# haltium_flpr register map
Vendor: Nordic Semiconductor; Series: nRFHaltium; File version: 1
Registers are 32-bit, read-write, reset 0x0 unless marked. A register's access mark holds for its fields unless they carry their own. Offsets are from the block's base; [hi:lo] are bit positions; {n}, {i} and the like mark numbered series; 'fields as' and 'values as' point back to an identical list.

## GLOBAL_USBHSCORE0_NS (part 1 of 2) — USBHSCORE
Base 0x2F700000
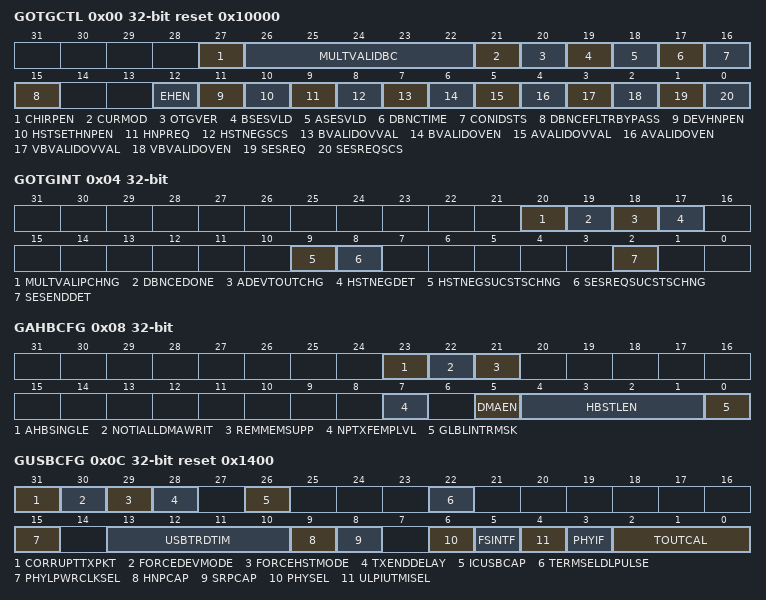
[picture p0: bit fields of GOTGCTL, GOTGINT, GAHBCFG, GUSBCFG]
0x00 GOTGCTL reset 0x10000 — OTG Control and Status Register
  [27] CHIRPEN — Mode: Device Only
    0=CHIRP_DISABLE (Unspecified); 1=CHIRP_ENABLE (Unspecified)
  [26:22] MULTVALIDBC ro — Mode: Host and Device. Multi Valued ID pin (MultValIdBC)
    1=RID_C (Unspecified); 2=RID_B (Unspecified); 4=RID_A (Unspecified); 8=RID_GND (Unspecified); 16=RID_FLOAT (Unspecified)
  [21] CURMOD ro — Current Mode of Operation (CurMod)
    0=DEVICEMODE (Unspecified); 1=HOSTMODE (Unspecified)
  [20] OTGVER — OTG Version (OTGVer)
    0=VER13 (Unspecified); 1=VER20 (Unspecified)
  [19] BSESVLD ro — Mode: Device only. B-Session Valid (BSesVld)
    0=NOTVALID (Unspecified); 1=VALID (Unspecified)
  [18] ASESVLD ro — Mode: Host only. A-Session Valid (ASesVld)
    0=NOTVALID (Unspecified); 1=VALID (Unspecified)
  [17] DBNCTIME ro — Mode: Host only. Long/Short Debounce Time (DbncTime)
    0=LONG (Unspecified); 1=SHORT (Unspecified)
  [16] CONIDSTS ro — Mode: Host and Device. Connector ID Status (ConIDSts)
    0=MODEA (Unspecified); 1=MODEB (Unspecified)
  [15] DBNCEFLTRBYPASS — Mode: Host and Device
    0=DISABLED (Unspecified); 1=ENABLED (Unspecified)
  [12] EHEN — Mode: SRP Capable Host. Embedded Host Enable (EHEn)
    0=EHDISABLE (Unspecified); 1=EHENABLE (Unspecified)
  [11] DEVHNPEN — Mode: HNP Capable OTG DeviceDevice HNP Enabled (DevHNPEn)
    0=DISABLED (Unspecified); 1=ENABLED (Unspecified)
  [10] HSTSETHNPEN — Mode: HNP Capable OTG Host. Host Set HNP Enable (HstSetHNPEn)
    0=DISABLED (Unspecified); 1=ENABLED (Unspecified)
  [9] HNPREQ — Mode: HNP Capable OTG DeviceHNP Request (HNPReq)
    0=DISABLED (Unspecified); 1=ENABLED (Unspecified)
  [8] HSTNEGSCS ro — Mode: HNP-capable DeviceHost Negotiation Success (HstNegScs)
    0=FAIL (Unspecified); 1=SUCCESS (Unspecified)
  [7] BVALIDOVVAL — Mode: Device only. B-Peripheral Session Valid OverrideValue (BvalidOvVal)
    0=Unspecified; 1=Unspecified
  [6] BVALIDOVEN — Mode: Device only. B-Peripheral Session Valid Override Value (BvalidOvEn)
    0=DISABLED (Unspecified); 1=ENABLED (Unspecified)
  [5] AVALIDOVVAL — Mode: Host only A-Peripheral Session Valid OverrideValue (AvalidOvVal)
    0=Unspecified; 1=Unspecified
  [4] AVALIDOVEN — Mode: Host only. A-Peripheral Session Valid Override Enable (AvalidOvEn)
    0=DISABLED (Unspecified); 1=ENABLED (Unspecified)
  [3] VBVALIDOVVAL — Mode: Host only. VBUS Valid OverrideValue (VbvalidOvVal)
    0=SET0 (Unspecified); 1=SET1 (Unspecified)
  [2] VBVALIDOVEN — Mode: Host only. VBUS Valid Override Enable (VbvalidOvEn)
    0=DISABLED (Unspecified); 1=ENABLED (Unspecified)
  [1] SESREQ — Mode: Device only. Session Request (SesReq)
    0=NOREQUEST (Unspecified); 1=REQUEST (Unspecified)
  [0] SESREQSCS ro — Mode: Device only. Session Request Success (SesReqScs)
    0=FAIL (Unspecified); 1=SUCCESS (Unspecified)
0x04 GOTGINT — OTG Interrupt Register
  [20] MULTVALIPCHNG — This bit when set indicates that there is a change in the value of at least one ACA pin value.
    0=NO_ACA_PIN_CHANGE (Unspecified); 1=ACA_PIN_CHANGE (Unspecified)
  [19] DBNCEDONE — Mode: Host only. Debounce Done (DbnceDone)
    0=INACTIVE (Unspecified); 1=ACTIVE (Unspecified)
  [18] ADEVTOUTCHG — Mode: Host and Device. A-Device Timeout Change (ADevTOUTChg)
    0=INACTIVE (Unspecified); 1=ACTIVE (Unspecified)
  [17] HSTNEGDET — Mode:Host and Device. Host Negotiation Detected (HstNegDet)
    0=INACTIVE (Unspecified); 1=ACTIVE (Unspecified)
  [9] HSTNEGSUCSTSCHNG — Mode: Host and Device. Host Negotiation Success Status Change (HstNegSucStsChng)
    0=INACTIVE (Unspecified); 1=ACTIVE (Unspecified)
  [8] SESREQSUCSTSCHNG — Mode: Host and Device. Session Request Success Status Change (SesReqSucStsChng)
    0=INACTIVE (Unspecified); 1=ACTIVE (Unspecified)
  [2] SESENDDET — Mode: Host and Device. Session End Detected (SesEndDet)
    0=INACTIVE (Unspecified); 1=ACTIVE (Unspecified)
0x08 GAHBCFG — AHB Configuration Register
  [23] AHBSINGLE — Mode: Host and Device. AHB Single Support (AHBSingle)
    0=INCRBURST (Unspecified); 1=SINGLEBURST (Unspecified)
  [22] NOTIALLDMAWRIT — Mode: Host and Device. Notify All DMA Write Transactions (NotiAllDmaWrit)
    0=LASTTRANS (Unspecified); 1=ALLTRANS (Unspecified)
  [21] REMMEMSUPP — Mode: Host and Device. Remote Memory Support (RemMemSupp)
    0=DISABLED (Unspecified); 1=ENABLED (Unspecified)
  [7] NPTXFEMPLVL — Mode: Host and device. Non-Periodic TxFIFO Empty Level (NPTxFEmpLvl)
    0=HALFEMPTY (Unspecified); 1=EMPTY (Unspecified)
  [5] DMAEN — Mode: Host and device. DMA Enable (DMAEn)
    0=SLAVEMODE (Unspecified); 1=DMAMODE (Unspecified)
  [4:1] HBSTLEN — Mode: Host and device. Burst Length/Type (HBstLen)
    0=WORD1ORSINGLE (Unspecified); 1=WORD4ORINCR (Unspecified); 2=WORD8 (Unspecified); 3=WORD16ORINCR4 (Unspecified); 4=WORD32 (Unspecified); 5=WORD64ORINCR8 (Unspecified); 6=WORD128 (Unspecified); 7=WORD256ORINCR16 (Unspecified); 8=WORDX (Unspecified)
  [0] GLBLINTRMSK — Mode: Host and device. Global Interrupt Mask (GlblIntrMsk)
    0=MASK (Unspecified); 1=NOMASK (Unspecified)
0x0C GUSBCFG reset 0x1400 — USB Configuration Register
  [31] CORRUPTTXPKT wo — Mode: Host and device. Corrupt Tx packet (CorruptTxPkt)
    0=Disabled (Unspecified); 1=Enabled (Unspecified)
  [30] FORCEDEVMODE — Mode:Host and device. Force Device Mode (ForceDevMode)
    0=DISABLED (Unspecified); 1=ENABLED (Unspecified)
  [29] FORCEHSTMODE — Mode: Host and device. Force Host Mode (ForceHstMode)
    0=DISABLED (Unspecified); 1=ENABLED (Unspecified)
  [28] TXENDDELAY — Mode: Device only. Tx End Delay (TxEndDelay)
    0=DISABLED (Unspecified); 1=ENABLED (Unspecified)
  [26] ICUSBCAP ro — Mode: Host and Device. IC_USB-Capable (IC_USBCap)
    0=NOTSELECTED (Unspecified); 1=SELECTED (Unspecified)
  [22] TERMSELDLPULSE — Mode: Device only. TermSel DLine Pulsing Selection (TermSelDLPulse)
    0=TXVALID (Unspecified); 1=TERMSEL (Unspecified)
  [15] PHYLPWRCLKSEL — PHY Low-Power Clock Select (PhyLPwrClkSel)
    0=INTPLLCLK (Unspecified); 1=EXTCLK (Unspecified)
  [13:10] USBTRDTIM — Mode: Device only. USB Turnaround Time (USBTrdTim)
    5=TURNTIME16BIT (Unspecified); 9=TURNTIME8BIT (Unspecified)
  [9] HNPCAP — Mode: Host and Device. HNP-Capable (HNPCap)
    0=DISABLED (Unspecified); 1=ENABLED (Unspecified)
  [8] SRPCAP — Mode: Host and Device. SRP-Capable (SRPCap)
    0=DISABLED (Unspecified); 1=ENABLED (Unspecified)
  [6] PHYSEL ro
    0=USB20 (Unspecified); 1=USB11 (Unspecified)
  [5] FSINTF ro — Mode: Host and Device. Full-Speed Serial Interface Select (FSIntf)
    0=FS6PIN (Unspecified); 1=FS3PIN (Unspecified)
  [4] ULPIUTMISEL ro — Mode: Host and Device. ULPI or UTMI+ Select (ULPI_UTMI_Sel)
    0=UTMI (Unspecified); 1=ULPI (Unspecified)
  [3] PHYIF — Mode: Host and Device. PHY Interface (PHYIf)
    0=BITS8 (Unspecified); 1=BITS16 (Unspecified)
  [2:0] TOUTCAL — Mode: Host and Device. HS/FS Timeout Calibration (TOutCal)
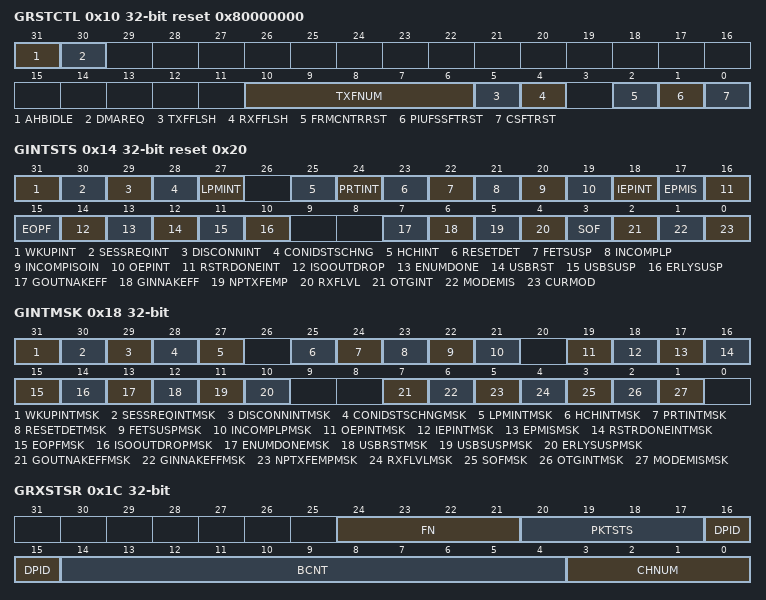
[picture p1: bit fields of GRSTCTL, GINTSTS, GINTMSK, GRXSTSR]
0x10 GRSTCTL reset 0x80000000 — Reset Register
  [31] AHBIDLE ro — Mode: Host and Device. AHB Master Idle (AHBIdle)
    0=INACTIVE (Unspecified); 1=ACTIVE (Unspecified)
  [30] DMAREQ ro — Mode: Host and Device. DMA Request Signal (DMAReq)
    0=INACTIVE (Unspecified); 1=ACTIVE (Unspecified)
  [10:6] TXFNUM — Mode: Host and Device. TxFIFO Number (TxFNum)
    {v}=TXF{v} (Unspecified) (v=0..16)
  [5] TXFFLSH — Mode: Host and Device. TxFIFO Flush (TxFFlsh)
    0=INACTIVE (Unspecified); 1=ACTIVE (Unspecified)
  [4] RXFFLSH — Mode: Host and Device. RxFIFO Flush (RxFFlsh)
    0=INACTIVE (Unspecified); 1=ACTIVE (Unspecified)
  [2] FRMCNTRRST — Mode: Host only. Host Frame Counter Reset (FrmCntrRst)
    0=NOTACTIVE (Unspecified); 1=ACTIVE (Unspecified)
  [1] PIUFSSFTRST — Mode: Host and Device. PIU FS Dedicated Controller Soft Reset (PIUFSSftRst)
    0=RESET_INACTIVE (Unspecified); 1=RESET_ACTIVE (Unspecified)
  [0] CSFTRST — Mode: Host and Device. Core Soft Reset (CSftRst)
    0=NOTACTIVE (Unspecified); 1=ACTIVE (Unspecified)
0x14 GINTSTS reset 0x20 — Interrupt Register
  [31] WKUPINT — Mode: Host and Device. Resume/Remote Wakeup Detected Interrupt (WkUpInt)
    0=INACTIVE (Unspecified); 1=ACTIVE (Unspecified)
  [30] SESSREQINT — Mode: Host and Device. Session Request/New Session Detected Interrupt (SessReqInt)
    0=INACTIVE (Unspecified); 1=ACTIVE (Unspecified)
  [29] DISCONNINT — Mode: Host only. Disconnect Detected Interrupt (DisconnInt)
    0=INACTIVE (Unspecified); 1=ACTIVE (Unspecified)
  [28] CONIDSTSCHNG — Mode: Host and Device. Connector ID Status Change (ConIDStsChng)
    0=INACTIVE (Unspecified); 1=ACTIVE (Unspecified)
  [27] LPMINT — Mode: Host and Device
    0=INACTIVE (Unspecified); 1=ACTIVE (Unspecified)
  [25] HCHINT ro — Mode: Host only. Host Channels Interrupt (HChInt)
    0=INACTIVE (Unspecified); 1=ACTIVE (Unspecified)
  [24] PRTINT ro — Mode: Host only. Host Port Interrupt (PrtInt)
    0=INACTIVE (Unspecified); 1=ACTIVE (Unspecified)
  [23] RESETDET — Mode: Device only. Reset detected Interrupt (ResetDet)
    0=INACTIVE (Unspecified); 1=ACTIVE (Unspecified)
  [22] FETSUSP — Mode: Device only. Data Fetch Suspended (FetSusp)
    0=INACTIVE (Unspecified); 1=ACTIVE (Unspecified)
  [21] INCOMPLP — Incomplete Periodic Transfer (incomplP)
    0=INACTIVE (Unspecified); 1=ACTIVE (Unspecified)
  [20] INCOMPISOIN — Mode: Device only. Incomplete Isochronous IN Transfer (incompISOIN)
    0=INACTIVE (Unspecified); 1=ACTIVE (Unspecified)
  [19] OEPINT ro — Mode: Device only. OUT Endpoints Interrupt (OEPInt)
    0=INACTIVE (Unspecified); 1=ACTIVE (Unspecified)
  [18] IEPINT ro — Mode: Device only. IN Endpoints Interrupt (IEPInt)
    0=INACTIVE (Unspecified); 1=ACTIVE (Unspecified)
  [17] EPMIS — Mode: Device only. Endpoint Mismatch Interrupt (EPMis)
    0=INACTIVE (Unspecified); 1=ACTIVE (Unspecified)
  [16] RSTRDONEINT — Mode: Device only. Restore Done Interrupt (RstrDoneInt)
    0=INACTIVE (Unspecified); 1=ACTIVE (Unspecified)
  [15] EOPF — Mode: Device only. End of Periodic Frame Interrupt (EOPF)
    0=INACTIVE (Unspecified); 1=ACTIVE (Unspecified)
  [14] ISOOUTDROP — Mode: Device only. Isochronous OUT Packet Dropped Interrupt (ISOOutDrop)
    0=INACTIVE (Unspecified); 1=ACTIVE (Unspecified)
  [13] ENUMDONE — Mode: Device only. Enumeration Done (EnumDone)
    0=INACTIVE (Unspecified); 1=ACTIVE (Unspecified)
  [12] USBRST — Mode: Device only. USB Reset (USBRst)
    0=INACTIVE (Unspecified); 1=ACTIVE (Unspecified)
  [11] USBSUSP — Mode: Device only. USB Suspend (USBSusp)
    0=INACTIVE (Unspecified); 1=ACTIVE (Unspecified)
  [10] ERLYSUSP — Mode: Device only. Early Suspend (ErlySusp)
    0=INACTIVE (Unspecified); 1=ACTIVE (Unspecified)
  [7] GOUTNAKEFF ro — Mode: Device only. Global OUT NAK Effective (GOUTNakEff)
    0=INACTIVE (Unspecified); 1=ACTIVE (Unspecified)
  [6] GINNAKEFF ro — Mode: Device only. Global IN Non-periodic NAK Effective (GINNakEff)
    0=INACTIVE (Unspecified); 1=ACTIVE (Unspecified)
  [5] NPTXFEMP ro — Mode: Host and Device. Non-periodic TxFIFO Empty (NPTxFEmp)
    0=INACTIVE (Unspecified); 1=ACTIVE (Unspecified)
  [4] RXFLVL ro — Mode: Host and Device. RxFIFO Non-Empty (RxFLvl)
    0=INACTIVE (Unspecified); 1=ACTIVE (Unspecified)
  [3] SOF — Mode: Host and Device. Start of (micro)Frame (Sof)
    0=INTACTIVE (Unspecified); 1=ACTIVE (Unspecified)
  [2] OTGINT ro — Mode: Host and Device. OTG Interrupt (OTGInt)
    0=INACTIVE (Unspecified); 1=ACTIVE (Unspecified)
  [1] MODEMIS — Mode: Host and Device. Mode Mismatch Interrupt (ModeMis)
    0=INACTIVE (Unspecified); 1=ACTIVE (Unspecified)
  [0] CURMOD ro — Mode: Host and Device. Current Mode of Operation (CurMod)
    0=DEVICE (Unspecified); 1=HOST (Unspecified)
0x18 GINTMSK — Interrupt Mask Register
  [all] fields
    0=MASK (Unspecified); 1=NOMASK (Unspecified)
  [31] WKUPINTMSK — Mode: Host and Device. Resume/Remote Wakeup Detected Interrupt Mask (WkUpIntMsk)
  [30] SESSREQINTMSK — Mode: Host and Device
  [29] DISCONNINTMSK — Mode: Host and Device
  [28] CONIDSTSCHNGMSK — Mode: Host and Device
  [27] LPMINTMSK — Mode: Host and Device. LPM Transaction Received Interrupt (LPM_Int)
  [25] HCHINTMSK — Mode: Host only. Host Channels Interrupt Mask (HChIntMsk)
  [24] PRTINTMSK — Mode: Host only. Host Port Interrupt Mask (PrtIntMsk)
  [23] RESETDETMSK — Mode: Device only. Reset detected Interrupt Mask (ResetDetMsk)
  [22] FETSUSPMSK — Mode: Device only. Data Fetch Suspended Mask (FetSuspMsk)
  [21] INCOMPLPMSK — Incomplete Periodic Transfer Mask (incomplPMsk)
  [19] OEPINTMSK — Mode: Device only. OUT Endpoints Interrupt Mask (OEPIntMsk)
  [18] IEPINTMSK — Mode: Device only. IN Endpoints Interrupt Mask (IEPIntMsk)
  [17] EPMISMSK — Mode: Device only. Endpoint Mismatch Interrupt Mask (EPMisMsk)
  [16] RSTRDONEINTMSK — Mode: Host and Device
  [15] EOPFMSK — Mode: Device only. End of Periodic Frame Interrupt Mask (EOPFMsk)
  [14] ISOOUTDROPMSK — Mode: Device only. Isochronous OUT Packet Dropped Interrupt Mask (ISOOutDropMsk)
  [13] ENUMDONEMSK — Mode: Device only. Enumeration Done Mask (EnumDoneMsk)
  [12] USBRSTMSK — Mode: Device only. USB Reset Mask (USBRstMsk)
  [11] USBSUSPMSK — Mode: Device only. USB Suspend Mask (USBSuspMsk)
  [10] ERLYSUSPMSK — Mode: Device only. Early Suspend Mask (ErlySuspMsk)
  [7] GOUTNAKEFFMSK — Mode: Device only. Global OUT NAK Effective Mask (GOUTNakEffMsk)
  [6] GINNAKEFFMSK — Mode: Device only,
  [5] NPTXFEMPMSK — Mode: Host and Device
  [4] RXFLVLMSK — Mode: Host and Device
  [3] SOFMSK — Mode: Host and Device
  [2] OTGINTMSK — Mode: Host and Device
  [1] MODEMISMSK — Mode: Host and Device
0x1C GRXSTSR — Receive Status Debug Read Register
  [24:21] FN ro — Mode: Device only. Frame Number (FN)
  [20:17] PKTSTS ro — Packet Status (PktSts) indicates the status of the received packet.
    1=OUTNAK (Unspecified); 2=INOUTDPRX (Unspecified); 3=INOUTTRCOM (Unspecified); 4=DSETUPCOM (Unspecified); 5=DTTOG (Unspecified); 6=DSETUPRX (Unspecified); 7=CHHALT (Unspecified)
  [16:15] DPID ro — Data PID (DPID)
    0=DATA0 (Unspecified); 1=DATA2 (Unspecified); 2=DATA1 (Unspecified); 3=MDATA (Unspecified)
  [14:4] BCNT ro — Byte Count (BCnt)
  [3:0] CHNUM ro — Channel Number (ChNum)
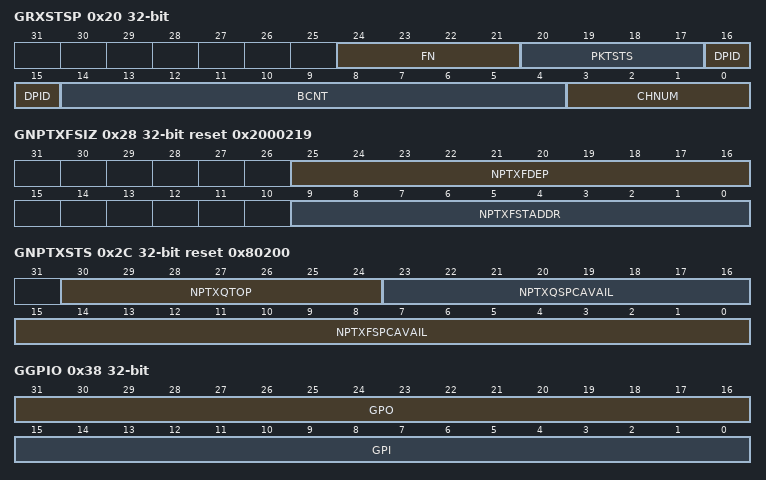
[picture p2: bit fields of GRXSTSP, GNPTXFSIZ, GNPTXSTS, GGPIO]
0x20 GRXSTSP — Receive Status Read/Pop Register
  [24:21] FN ro — Mode: Device only. Frame Number (FN)
  [20:17] PKTSTS ro — Packet Status (PktSts) indicates the status of the received packet.
    1=OUTNAK (Unspecified); 2=INOUTDPRX (Unspecified); 3=INOUTTRCOM (Unspecified); 4=DSETUPCOM (Unspecified); 5=DTTOG (Unspecified)
  [16:15] DPID ro — Data PID (DPID)
    values as GRXSTSR.DPID
  [14:4] BCNT ro — Byte Count (BCnt)
  [3:0] CHNUM ro — Channel Number (ChNum)
    {v}=CHEP{v} (Unspecified) (v=0..15)
0x24 GRXFSIZ reset 0x219 — Receive FIFO Size Register
  [9:0] RXFDEP — Mode: Host and Device. RxFIFO Depth (RxFDep)
0x28 GNPTXFSIZ reset 0x2000219 — Non-periodic Transmit FIFO Size Register
  [25:16] NPTXFDEP — Mode: Host only. Non-periodic TxFIFO Depth (NPTxFDep)
  [9:0] NPTXFSTADDR — Non-periodic Transmit RAM Start Address (NPTxFStAddr)
0x2C GNPTXSTS reset 0x80200 — Non-periodic Transmit FIFO/Queue Status Register
  [30:24] NPTXQTOP ro — Top of the Non-periodic Transmit Request Queue (NPTxQTop)
    0=INOUTTK (Unspecified); 1=ZEROTX (Unspecified); 2=PINGCSPLIT (Unspecified); 3=CHNHALT (Unspecified)
  [23:16] NPTXQSPCAVAIL ro — Non-periodic Transmit Request Queue Space Available (NPTxQSpcAvail)
    0=FULL (Unspecified); {v}=QUE{v} (Unspecified) (v=1..8)
  [15:0] NPTXFSPCAVAIL ro — Non-periodic TxFIFO Space Avail (NPTxFSpcAvail)
0x38 GGPIO — General Purpose Input/Output Register
  [31:16] GPO — General Purpose Output (GPO)
  [15:0] GPI ro — General Purpose Input (GPI)
0x3C GUID reset 0x12345678 — User ID Register
  [31:0] GUID — User ID (UserID)
0x40 GSNPSID reset 0x4F54400A — Synopsys ID Register
  [31:0] SYNOPSYSID ro — Release number of the controller being used currently.
0x44 GHWCFG1 reset 0xAA555000 — User Hardware Configuration 1 Register
  [31:0] EPDIR ro — This 32-bit field uses two bits per
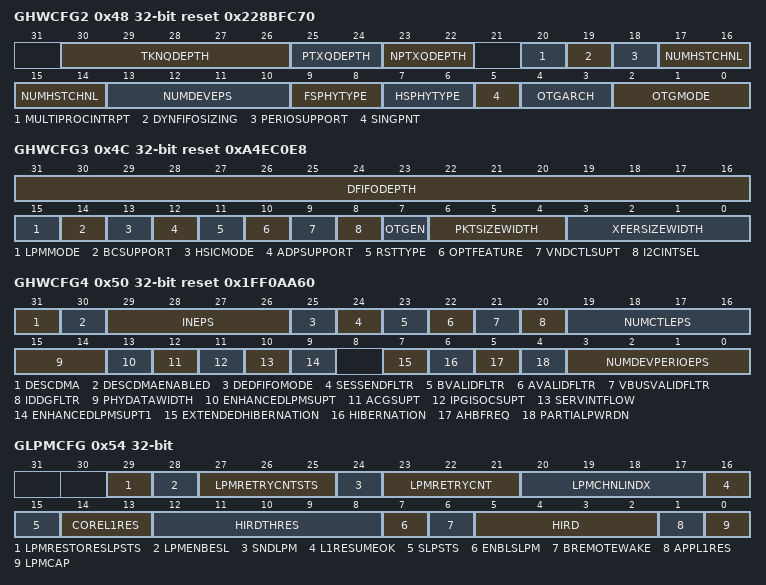
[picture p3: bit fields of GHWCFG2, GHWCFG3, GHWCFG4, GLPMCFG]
0x48 GHWCFG2 reset 0x228BFC70 — User Hardware Configuration 2 Register
  [30:26] TKNQDEPTH ro — Device Mode IN Token Sequence Learning Queue Depth (TknQDepth)
  [25:24] PTXQDEPTH ro — Host Mode Periodic Request Queue Depth (PTxQDepth)
    0=QUE2 (Unspecified); 1=QUE4 (Unspecified); 2=QUE8 (Unspecified); 3=QUE16 (Unspecified)
  [23:22] NPTXQDEPTH ro — Non-periodic Request Queue Depth (NPTxQDepth)
    0=TWO (Unspecified); 1=FOUR (Unspecified); 2=EIGHT (Unspecified)
  [20] MULTIPROCINTRPT ro — Multi Processor Interrupt Enabled (MultiProcIntrpt)
    0=DISABLED (Unspecified); 1=ENABLED (Unspecified)
  [19] DYNFIFOSIZING ro — Dynamic FIFO Sizing Enabled (DynFifoSizing)
    0=DISABLED (Unspecified); 1=ENABLED (Unspecified)
  [18] PERIOSUPPORT ro — Periodic OUT Channels Supported in Host Mode (PerioSupport)
    0=DISABLED (Unspecified); 1=ENABLED (Unspecified)
  [17:14] NUMHSTCHNL ro — Number of Host Channels (NumHstChnl)
    {v}=HOSTCH{v} (Unspecified) (v=0..15)
  [13:10] NUMDEVEPS ro — Number of Device Endpoints (NumDevEps)
    {v}=ENDPT{v} (Unspecified) (v=0..15)
  [9:8] FSPHYTYPE ro — Full-Speed PHY Interface Type (FSPhyType)
    0=NO_FS (Unspecified); 1=FS (Unspecified); 2=FSPLUSUTMI (Unspecified); 3=FSPLUSULPI (Unspecified)
  [7:6] HSPHYTYPE ro — High-Speed PHY Interface Type (HSPhyType)
    0=NOHS (Unspecified); 1=UTMIPLUS (Unspecified); 2=ULPI (Unspecified); 3=UTMIPUSULPI (Unspecified)
  [5] SINGPNT ro — Point-to-Point (SingPnt)
    0=MULTIPOINT (Unspecified); 1=SINGLEPOINT (Unspecified)
  [4:3] OTGARCH ro — Architecture (OtgArch)
    0=SLAVEMODE (Unspecified); 1=EXTERNALDMA (Unspecified); 2=INTERNALDMA (Unspecified)
  [2:0] OTGMODE ro — Mode of Operation (OtgMode). - 3b000:
    0=HNPSRP (Unspecified); 1=SRPOTG (Unspecified); 2=NHNPNSRP (Unspecified); 3=SRPCAPD (Unspecified); 4=NONOTGD (Unspecified); 5=SRPCAPH (Unspecified); 6=NONOTGH (Unspecified)
0x4C GHWCFG3 reset 0xA4EC0E8 — User Hardware Configuration 3 Register
  [31:16] DFIFODEPTH ro — DFIFO Depth (DfifoDepth - EP_LOC_CNT)
  [15] LPMMODE ro — LPM mode specified for Mode of Operation.
    0=DISABLED (Unspecified); 1=ENABLED (Unspecified)
  [14] BCSUPPORT ro — This bit indicates the controller support for Battery Charger.
    0=DISABLED (Unspecified); 1=ENABLED (Unspecified)
  [13] HSICMODE ro — HSIC mode specified for Mode of Operation
    0=DISABLED (Unspecified); 1=ENABLED (Unspecified)
  [12] ADPSUPPORT ro — This bit indicates whether ADP logic is present within or external to the controller
    0=DISABLED (Unspecified); 1=ENABLED (Unspecified)
  [11] RSTTYPE ro — Reset Style for Clocked always Blocks in RTL (RstType)
    0=ASYNCRST (Unspecified); 1=SYNCRST (Unspecified)
  [10] OPTFEATURE ro — Optional Features Removed (OptFeature)
    0=DISABLED (Unspecified); 1=ENABLED (Unspecified)
  [9] VNDCTLSUPT ro — Vendor Control Interface Support (VndctlSupt)
    0=DISABLED (Unspecified); 1=ENABLED (Unspecified)
  [8] I2CINTSEL ro — I2C Selection (I2CIntSel)
    0=DISABLED (Unspecified); 1=ENABLED (Unspecified)
  [7] OTGEN ro — OTG Function Enabled (OtgEn)
    0=DISABLED (Unspecified); 1=ENABLED (Unspecified)
  [6:4] PKTSIZEWIDTH ro — Width of Packet Size Counters (PktSizeWidth)
    {v}=BITS{v+4} (Unspecified) (v=0..6)
  [3:0] XFERSIZEWIDTH ro — Width of Transfer Size Counters (XferSizeWidth)
    {v}=WIDTH{v+11} (Unspecified) (v=0..8)
0x50 GHWCFG4 reset 0x1FF0AA60 — User Hardware Configuration 4 Register
  [31] DESCDMA ro — Scatter/Gather DMA configuration
    0=CONFIG1 (Unspecified); 1=CONFIG2 (Unspecified)
  [30] DESCDMAENABLED ro — Scatter/Gather DMA configuration
    0=DISABLE (Unspecified); 1=ENABLE (Unspecified)
  [29:26] INEPS ro — Number of Device Mode IN Endpoints Including Control Endpoints (INEps)
    {v}=ENDPT{v+1} (Unspecified) (v=0..15)
  [25] DEDFIFOMODE ro — Enable Dedicated Transmit FIFO for device IN Endpoints
    0=DISABLED (Unspecified); 1=ENABLED (Unspecified)
  [24] SESSENDFLTR ro — session_end Filter Enabled (SessEndFltr)
    0=DISABLED (Unspecified); 1=ENABLED (Unspecified)
  [23] BVALIDFLTR ro — b_valid Filter Enabled (BValidFltr)
    0=DISABLED (Unspecified); 1=ENABLED (Unspecified)
  [22] AVALIDFLTR ro — a_valid Filter Enabled (AValidFltr)
    0=DISABLED (Unspecified); 1=ENABLED (Unspecified)
  [21] VBUSVALIDFLTR ro — VBUS Valid Filter Enabled (VBusValidFltr)
    0=DISABLED (Unspecified); 1=ENABLED (Unspecified)
  [20] IDDGFLTR ro — IDDIG Filter Enable (IddgFltr)
    0=DISABLED (Unspecified); 1=ENABLED (Unspecified)
  [19:16] NUMCTLEPS ro — Number of Device Mode Control Endpoints in Addition to
    {v}=ENDPT{v} (Unspecified) (v=0..15)
  [15:14] PHYDATAWIDTH ro — UTMI+ PHY/ULPI-to-Internal UTMI+ Wrapper Data Width
    0=WIDTH1 (Unspecified); 1=WIDTH2 (Unspecified); 2=WIDTH3 (Unspecified)
  [13] ENHANCEDLPMSUPT ro — Enhanced LPM Support (EnhancedLPMSupt)
    1=ENABLED (Unspecified)
  [12] ACGSUPT ro — Active Clock Gating Support
    0=DISABLED (Unspecified); 1=ENABLED (Unspecified)
  [11] IPGISOCSUPT ro — Interpacket Gap ISOC OUT Worst-case Support (ipgisocSupt)
    0=DISABLED (Unspecified); 1=ENABLED (Unspecified)
  [10] SERVINTFLOW ro — Service Interval Flow
    0=DISABLED (Unspecified); 1=ENABLED (Unspecified)
  [9] ENHANCEDLPMSUPT1 ro — Enhanced LPM Support1 (EnhancedLPMSupt1)
    0=DISABLED (Unspecified); 1=ENABLED (Unspecified)
  [7] EXTENDEDHIBERNATION ro — Enable Hibernation
    0=DISABLED (Unspecified); 1=ENABLED (Unspecified)
  [6] HIBERNATION ro — Enable Hibernation (Hibernation)
    0=DISABLED (Unspecified); 1=ENABLED (Unspecified)
  [5] AHBFREQ ro — Minimum AHB Frequency Less Than 60 MHz (AhbFreq)
    0=DISABLED (Unspecified); 1=ENABLED (Unspecified)
  [4] PARTIALPWRDN ro — Enable Partial Power Down (PartialPwrDn)
    0=DISABLED (Unspecified); 1=ENABLED (Unspecified)
  [3:0] NUMDEVPERIOEPS ro — Number of Device Mode Periodic IN Endpoints (NumDevPerioEps)
0x54 GLPMCFG — LPM Config Register
  [29] LPMRESTORESLPSTS — LPM Restore Sleep Status (LPM_RestoreSlpSts)
    0=DISABLED (Unspecified); 1=ENABLED (Unspecified)
  [28] LPMENBESL — LPM Enable BESL (LPM_EnBESL)
    0=DISABLED (Unspecified); 1=ENABLED (Unspecified)
  [27:25] LPMRETRYCNTSTS ro — LPM Retry Count Status (LPM_RetryCnt_Sts)
    {v}=RETRY_REM{v} (Unspecified) (v=0..7)
  [24] SNDLPM — Send LPM Transaction (SndLPM)
    0=DISABLED (Unspecified); 1=ENABLED (Unspecified)
  [23:21] LPMRETRYCNT — LPM Retry Count (LPM_Retry_Cnt)
    {v}=RETRY{v} (Unspecified) (v=0..7)
  [20:17] LPMCHNLINDX — LPM Channel Index
    {v}=CH{v} (Unspecified) (v=0..15)
  [16] L1RESUMEOK ro — Sleep State Resume OK (L1ResumeOK)
    0=NOTOK (Unspecified); 1=OK (Unspecified)
  [15] SLPSTS ro — Port Sleep Status (SlpSts)
    0=CORE_NOT_IN_L1 (Unspecified); 1=CORE_IN_L1 (Unspecified)
  [14:13] COREL1RES ro — LPM Response (CoreL1Res)
    {v}=LPMRESP{v+1} (Unspecified) (v=0..3)
  [12:8] HIRDTHRES — BESL/HIRD Threshold (HIRD_Thres)
  [7] ENBLSLPM — Enable utmi_sleep_n (EnblSlpM)
    0=DISABLED (Unspecified); 1=ENABLED (Unspecified)
  [6] BREMOTEWAKE — RemoteWakeEnable (bRemoteWake)
    0=DISABLED (Unspecified); 1=ENABLED (Unspecified)
  [5:2] HIRD — Host-Initiated Resume Duration (HIRD)
  [1] APPL1RES — Mode: Device only. LPM response programmed by application (AppL1Res)
    0=NYET_RESP (Unspecified); 1=ACK_RESP (Unspecified)
  [0] LPMCAP — LPM-Capable (LPMCap)
    0=DISABLED (Unspecified); 1=ENABLED (Unspecified)
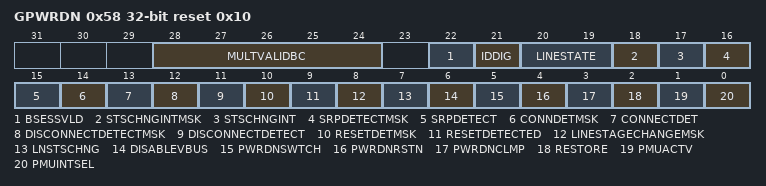
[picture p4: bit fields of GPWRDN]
0x58 GPWRDN reset 0x10 — Global Power Down register
  [28:24] MULTVALIDBC ro
    0=RID_0 (Unspecified); 1=RID_C (Unspecified); 2=RID_B (Unspecified); 4=RID_A (Unspecified); 8=RID_GND (Unspecified); 12=RID_A_RID_GND (Unspecified); 16=RID_FLOAT (Unspecified); 17=RID_C_RID_FLOAT (Unspecified); 18=RID_B_RID_FLOAT (Unspecified); 31=RID_1 (Unspecified)
  [22] BSESSVLD ro — B Session Valid (BSessVld)
    0=NOTVALID (Unspecified); 1=VALID (Unspecified)
  [21] IDDIG ro — This bit indicates the status of the signal IDDIG.
    0=DISABLED (Unspecified); 1=ENABLED (Unspecified)
  [20:19] LINESTATE ro
    {v}=LS{v+1} (Unspecified) (v=0..3)
  [18] STSCHNGINTMSK
    0=NOMASK (Unspecified); 1=MASK (Unspecified)
  [17] STSCHNGINT — Status Change Interrupt (StsChngInt)
    0=DISABLED (Unspecified); 1=ENABLED (Unspecified)
  [16] SRPDETECTMSK
    0=NOMASK (Unspecified); 1=MASK (Unspecified)
  [15] SRPDETECT
    0=DISABLED (Unspecified); 1=ENABLED (Unspecified)
  [14] CONNDETMSK
    0=NOMASK (Unspecified); 1=MASK (Unspecified)
  [13] CONNECTDET
    0=DISABLED (Unspecified); 1=ENABLED (Unspecified)
  [12] DISCONNECTDETECTMSK
    0=NOMASK (Unspecified); 1=MASK (Unspecified)
  [11] DISCONNECTDETECT
    0=DISABLED (Unspecified); 1=ENABLED (Unspecified)
  [10] RESETDETMSK
    0=NOMASK (Unspecified); 1=MASK (Unspecified)
  [9] RESETDETECTED
    0=DISABLED (Unspecified); 1=ENABLED (Unspecified)
  [8] LINESTAGECHANGEMSK
    0=NOMASK (Unspecified); 1=MASK (Unspecified)
  [7] LNSTSCHNG — Line State Change (LnStsChng)
    0=DISABLED (Unspecified); 1=ENABLED (Unspecified)
  [6] DISABLEVBUS
    0=DISABLED (Unspecified); 1=ENABLED (Unspecified)
  [5] PWRDNSWTCH — Power Down Switch (PwrDnSwtch)
    0=ON (Unspecified); 1=OFF (Unspecified)
  [4] PWRDNRSTN — Power Down ResetN (PwrDnRst_n)
    0=DISABLE (Unspecified); 1=ENABLE (Unspecified)
  [3] PWRDNCLMP — Power Down Clamp (PwrDnClmp)
    0=DISABLE (Unspecified); 1=ENABLE (Unspecified)
  [2] RESTORE
    0=DISABLE (Unspecified); 1=ENABLE (Unspecified)
  [1] PMUACTV — PMU Active (PMUActv)
    0=DISABLE (Unspecified); 1=ENABLE (Unspecified)
  [0] PMUINTSEL — PMU Interrupt Select (PMUIntSel)
    0=DISABLE (Unspecified); 1=ENABLE (Unspecified)

## Notices in the file
Copyright (c) 2010 - 2020, Nordic Semiconductor ASA
All rights reserved.
Redistribution and use in source and binary forms, with or without modification,
are permitted provided that the following conditions are met:
1. Redistributions of source code must retain the above copyright notice, this
list of conditions and the following disclaimer.
2. Redistributions in binary form, except as embedded into a Nordic
Semiconductor ASA integrated circuit in a product or a software update for
such product, must reproduce the above copyright notice, this list of
conditions and the following disclaimer in the documentation and/or other
materials provided with the distribution.
3. Neither the name of Nordic Semiconductor ASA nor the names of its
contributors may be used to endorse or promote products derived from this
software without specific prior written permission.
4. This software, with or without modification, must only be used with a
Nordic Semiconductor ASA integrated circuit.
5. Any software provided in binary form under this license must not be reverse
engineered, decompiled, modified and/or disassembled.
THIS SOFTWARE IS PROVIDED BY NORDIC SEMICONDUCTOR ASA "AS IS" AND ANY EXPRESS
OR IMPLIED WARRANTIES, INCLUDING, BUT NOT LIMITED TO, THE IMPLIED WARRANTIES
OF MERCHANTABILITY, NONINFRINGEMENT, AND FITNESS FOR A PARTICULAR PURPOSE ARE
DISCLAIMED. IN NO EVENT SHALL NORDIC SEMICONDUCTOR ASA OR CONTRIBUTORS BE
LIABLE FOR ANY DIRECT, INDIRECT, INCIDENTAL, SPECIAL, EXEMPLARY, OR
CONSEQUENTIAL DAMAGES (INCLUDING, BUT NOT LIMITED TO, PROCUREMENT OF SUBSTITUTE
GOODS OR SERVICES; LOSS OF USE, DATA, OR PROFITS; OR BUSINESS INTERRUPTION)
HOWEVER CAUSED AND ON ANY THEORY OF LIABILITY, WHETHER IN CONTRACT, STRICT
LIABILITY, OR TORT (INCLUDING NEGLIGENCE OR OTHERWISE) ARISING IN ANY WAY OUT
OF THE USE OF THIS SOFTWARE, EVEN IF ADVISED OF THE POSSIBILITY OF SUCH DAMAGE.
